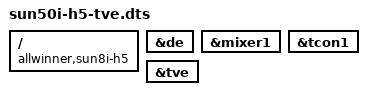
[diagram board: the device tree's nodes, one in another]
/dts-v1/;
/plugin/;

/ {
	compatible = "allwinner,sun8i-h5";

	fragment@0 {
		target = <&de>;
		__overlay__ {
			status = "okay";
		};
	};

	fragment@1 {
		target = <&mixer1>;
		__overlay__ {
			status = "okay";
		};
	};

	fragment@2 {
		target = <&tcon1>;
		 __overlay__ {
			status = "okay";
		};
	};

	fragment@3 {
		target = <&tve>;
		__overlay__ {
			status = "okay";
		};
	};
};
